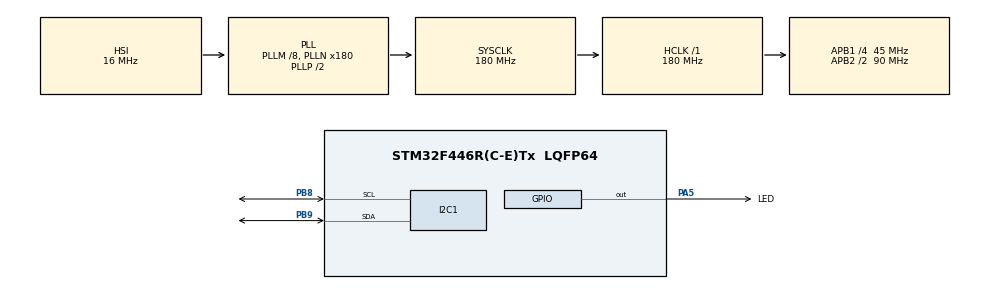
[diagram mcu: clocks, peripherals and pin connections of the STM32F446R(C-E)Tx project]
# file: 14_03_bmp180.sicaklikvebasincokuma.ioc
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Mcu.Family=STM32F4
PH0-OSC_IN.Signal=RCC_OSC_IN
RCC.CortexFreq_Value=180000000
RCC.APB1CLKDivider=RCC_HCLK_DIV4
RCC.SYSCLKSource=RCC_SYSCLKSOURCE_PLLCLK
ProjectManager.StackSize=0x400
PA13.Signal=SYS_JTMS-SWDIO
ProjectManager.TargetToolchain=STM32CubeIDE
I2C1.I2C_Mode=I2C_Fast
RCC.HCLKFreq_Value=180000000
PB9.Mode=I2C
RCC.APB2TimFreq_Value=180000000
RCC.USBFreq_Value=180000000
RCC.AHBFreq_Value=180000000
PH0-OSC_IN.Mode=HSE-External-Oscillator
PA5.Signal=GPIO_Output
RCC.HSE_VALUE=8000000
board=custom
RCC.VCOOutputFreq_Value=360000000
RCC.APB2Freq_Value=90000000
PA14.Mode=Serial_Wire
PH1-OSC_OUT.Signal=RCC_OSC_OUT
PA13.Mode=Serial_Wire
Mcu.Name=STM32F446R(C-E)Tx
PH1-OSC_OUT.Mode=HSE-External-Oscillator
RCC.SYSCLKFreq_VALUE=180000000
Mcu.Package=LQFP64
PB9.Signal=I2C1_SDA
PA5.GPIO_Label=LED
PA14.Signal=SYS_JTCK-SWCLK
ProjectManager.HeapSize=0x200
NVIC.PriorityGroup=NVIC_PRIORITYGROUP_4
RCC.APB2CLKDivider=RCC_HCLK_DIV2
RCC.PLLM=8
PB8.Mode=I2C
RCC.PLLN=180
RCC.APB1TimFreq_Value=90000000
PB8.Signal=I2C1_SCL
RCC.APB1Freq_Value=45000000

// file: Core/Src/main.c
/* USER CODE BEGIN Header */
/**
  ******************************************************************************
  * @file           : main.c
  * @brief          : Main program body
  ******************************************************************************
  * @attention
  *
  * <h2><center>&copy; Copyright (c) 2022 STMicroelectronics.
  * All rights reserved.</center></h2>
  *
  * This software component is licensed by ST under BSD 3-Clause license,
  * the "License"; You may not use this file except in compliance with the
  * License. You may obtain a copy of the License at:
  *                        opensource.org/licenses/BSD-3-Clause
  *
  ******************************************************************************
  */
/* USER CODE END Header */
#include "main.h"

/* USER CODE BEGIN Includes */
#include "bmp180.h"
/* USER CODE END Includes */

I2C_HandleTypeDef hi2c1;

/* USER CODE BEGIN PV */
float temperature=0;
float pressure=0;
float altitude=0;
/* USER CODE END PV */

void SystemClock_Config(void);
static void MX_GPIO_Init(void);
static void MX_I2C1_Init(void);

int main(void)
{

  /* MCU Configuration--------------------------------------------------------*/

  /* Reset of all peripherals, Initializes the Flash interface and the Systick. */
  HAL_Init();

  /* Configure the system clock */
  SystemClock_Config();

  /* Initialize all configured peripherals */
  MX_GPIO_Init();
  MX_I2C1_Init();
  /* USER CODE BEGIN 2 */
  BMP180_Init();
  BMP180_Get_Uncompensated_Temperature();
  BMP180_Get_Uncompensated_Pressure();
  /* USER CODE END 2 */

  /* Infinite loop */
  while (1)
  {

    /* USER CODE BEGIN 3 */
	  temperature = BMP180_Get_Temperature();
	  pressure = BMP180_Get_Pressure();
	  altitude = BMP180_Get_Altitude();
  }
  /* USER CODE END 3 */
}

void SystemClock_Config(void)
{
  RCC_OscInitTypeDef RCC_OscInitStruct = {0};
  RCC_ClkInitTypeDef RCC_ClkInitStruct = {0};

  /** Configure the main internal regulator output voltage
  */
  __HAL_RCC_PWR_CLK_ENABLE();
  __HAL_PWR_VOLTAGESCALING_CONFIG(PWR_REGULATOR_VOLTAGE_SCALE1);
  /** Initializes the RCC Oscillators according to the specified parameters
  * in the RCC_OscInitTypeDef structure.
  */
  RCC_OscInitStruct.OscillatorType = RCC_OSCILLATORTYPE_HSI;
  RCC_OscInitStruct.HSIState = RCC_HSI_ON;
  RCC_OscInitStruct.HSICalibrationValue = RCC_HSICALIBRATION_DEFAULT;
  RCC_OscInitStruct.PLL.PLLState = RCC_PLL_ON;
  RCC_OscInitStruct.PLL.PLLSource = RCC_PLLSOURCE_HSI;
  RCC_OscInitStruct.PLL.PLLM = 8;
  RCC_OscInitStruct.PLL.PLLN = 180;
  RCC_OscInitStruct.PLL.PLLP = RCC_PLLP_DIV2;
  RCC_OscInitStruct.PLL.PLLQ = 2;
  RCC_OscInitStruct.PLL.PLLR = 2;
  if (HAL_RCC_OscConfig(&RCC_OscInitStruct) != HAL_OK)
  {
    Error_Handler();
  }
  /** Activate the Over-Drive mode
  */
  if (HAL_PWREx_EnableOverDrive() != HAL_OK)
  {
    Error_Handler();
  }
  /** Initializes the CPU, AHB and APB buses clocks
  */
  RCC_ClkInitStruct.ClockType = RCC_CLOCKTYPE_HCLK|RCC_CLOCKTYPE_SYSCLK
                              |RCC_CLOCKTYPE_PCLK1|RCC_CLOCKTYPE_PCLK2;
  RCC_ClkInitStruct.SYSCLKSource = RCC_SYSCLKSOURCE_PLLCLK;
  RCC_ClkInitStruct.AHBCLKDivider = RCC_SYSCLK_DIV1;
  RCC_ClkInitStruct.APB1CLKDivider = RCC_HCLK_DIV4;
  RCC_ClkInitStruct.APB2CLKDivider = RCC_HCLK_DIV2;

  if (HAL_RCC_ClockConfig(&RCC_ClkInitStruct, FLASH_LATENCY_5) != HAL_OK)
  {
    Error_Handler();
  }
}

static void MX_I2C1_Init(void)
{

  hi2c1.Instance = I2C1;
  hi2c1.Init.ClockSpeed = 400000;
  hi2c1.Init.DutyCycle = I2C_DUTYCYCLE_2;
  hi2c1.Init.OwnAddress1 = 0;
  hi2c1.Init.AddressingMode = I2C_ADDRESSINGMODE_7BIT;
  hi2c1.Init.DualAddressMode = I2C_DUALADDRESS_DISABLE;
  hi2c1.Init.OwnAddress2 = 0;
  hi2c1.Init.GeneralCallMode = I2C_GENERALCALL_DISABLE;
  hi2c1.Init.NoStretchMode = I2C_NOSTRETCH_DISABLE;
  if (HAL_I2C_Init(&hi2c1) != HAL_OK)
  {
    Error_Handler();
  }

}

static void MX_GPIO_Init(void)
{
  GPIO_InitTypeDef GPIO_InitStruct = {0};

  /* GPIO Ports Clock Enable */
  __HAL_RCC_GPIOH_CLK_ENABLE();
  __HAL_RCC_GPIOA_CLK_ENABLE();
  __HAL_RCC_GPIOB_CLK_ENABLE();

  /*Configure GPIO pin Output Level */
  HAL_GPIO_WritePin(LED_GPIO_Port, LED_Pin, GPIO_PIN_RESET);

  /*Configure GPIO pin : LED_Pin */
  GPIO_InitStruct.Pin = LED_Pin;
  GPIO_InitStruct.Mode = GPIO_MODE_OUTPUT_PP;
  GPIO_InitStruct.Pull = GPIO_NOPULL;
  GPIO_InitStruct.Speed = GPIO_SPEED_FREQ_LOW;
  HAL_GPIO_Init(LED_GPIO_Port, &GPIO_InitStruct);

}

void Error_Handler(void)
{
  __disable_irq();
  while (1)
  {
  }
}

/************************ (C) COPYRIGHT STMicroelectronics *****END OF FILE****/
